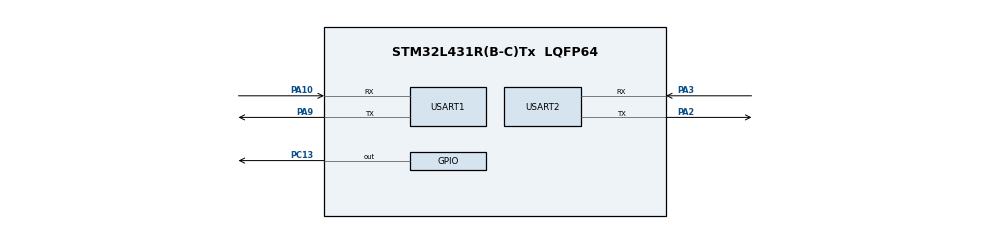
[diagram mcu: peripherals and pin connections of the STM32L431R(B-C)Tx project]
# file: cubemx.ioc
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Mcu.Family=STM32L4
Mcu.Name=STM32L431R(B-C)Tx
Mcu.Package=LQFP64
NVIC.PriorityGroup=NVIC_PRIORITYGROUP_4
NVIC.USART1_IRQn=true\:0\:0\:false\:false\:true\:true\:true
NVIC.USART2_IRQn=true\:0\:0\:false\:false\:true\:true\:true
PA10.Mode=Asynchronous
PA10.Signal=USART1_RX
PA13\ (JTMS-SWDIO).Mode=Serial_Wire
PA13\ (JTMS-SWDIO).Signal=SYS_JTMS-SWDIO
PA14\ (JTCK-SWCLK).Mode=Serial_Wire
PA14\ (JTCK-SWCLK).Signal=SYS_JTCK-SWCLK
PA2.Mode=Asynchronous
PA2.Signal=USART2_TX
PA3.Mode=Asynchronous
PA3.Signal=USART2_RX
PA9.Mode=Asynchronous
PA9.Signal=USART1_TX
PC13.Signal=GPIO_Output
PC14-OSC32_IN\ (PC14).Mode=LSE-External-Oscillator
PC14-OSC32_IN\ (PC14).Signal=RCC_OSC32_IN
PC15-OSC32_OUT\ (PC15).Mode=LSE-External-Oscillator
PC15-OSC32_OUT\ (PC15).Signal=RCC_OSC32_OUT
PH0-OSC_IN\ (PH0).Mode=HSE-External-Oscillator
PH0-OSC_IN\ (PH0).Signal=RCC_OSC_IN
PH1-OSC_OUT\ (PH1).Mode=HSE-External-Oscillator
PH1-OSC_OUT\ (PH1).Signal=RCC_OSC_OUT
ProjectManager.HeapSize=0x200
ProjectManager.StackSize=0x400
ProjectManager.TargetToolchain=MDK-ARM V5.27
RCC.HSE_VALUE=8000000
RCC.HSI48_VALUE=48000000
RCC.HSI_VALUE=16000000
RCC.MSI_VALUE=4000000
RCC.VCOOutputFreq_Value=32000000
USART1.VirtualMode-Asynchronous=VM_ASYNC
USART2.VirtualMode-Asynchronous=VM_ASYNC
board=custom

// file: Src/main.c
/* USER CODE BEGIN Header */
/**
  ******************************************************************************
  * @file           : main.c
  * @brief          : Main program body
  ******************************************************************************
  * @attention
  *
  * <h2><center>&copy; Copyright (c) 2021 STMicroelectronics.
  * All rights reserved.</center></h2>
  *
  * This software component is licensed by ST under BSD 3-Clause license,
  * the "License"; You may not use this file except in compliance with the
  * License. You may obtain a copy of the License at:
  *                        opensource.org/licenses/BSD-3-Clause
  *
  ******************************************************************************
  */
/* USER CODE END Header */
#include "main.h"

UART_HandleTypeDef huart1;
UART_HandleTypeDef huart2;

void SystemClock_Config(void);
static void MX_GPIO_Init(void);
static void MX_USART1_UART_Init(void);
static void MX_USART2_UART_Init(void);

__WEAK int main(void)
{

  /* MCU Configuration--------------------------------------------------------*/

  /* Reset of all peripherals, Initializes the Flash interface and the Systick. */

  /* Infinite loop */
  while (1)
  {

  }
}

void SystemClock_Config(void)
{
  RCC_OscInitTypeDef RCC_OscInitStruct = {0};
  RCC_ClkInitTypeDef RCC_ClkInitStruct = {0};
  RCC_PeriphCLKInitTypeDef PeriphClkInit = {0};

  /** Configure LSE Drive Capability
  */
  HAL_PWR_EnableBkUpAccess();
  __HAL_RCC_LSEDRIVE_CONFIG(RCC_LSEDRIVE_LOW);
  /** Initializes the RCC Oscillators according to the specified parameters
  * in the RCC_OscInitTypeDef structure.
  */
  RCC_OscInitStruct.OscillatorType = RCC_OSCILLATORTYPE_LSE|RCC_OSCILLATORTYPE_MSI;
  RCC_OscInitStruct.LSEState = RCC_LSE_ON;
  RCC_OscInitStruct.MSIState = RCC_MSI_ON;
  RCC_OscInitStruct.MSICalibrationValue = 0;
  RCC_OscInitStruct.MSIClockRange = RCC_MSIRANGE_6;
  RCC_OscInitStruct.PLL.PLLState = RCC_PLL_NONE;
  if (HAL_RCC_OscConfig(&RCC_OscInitStruct) != HAL_OK)
  {
    Error_Handler();
  }
  /** Initializes the CPU, AHB and APB buses clocks
  */
  RCC_ClkInitStruct.ClockType = RCC_CLOCKTYPE_HCLK|RCC_CLOCKTYPE_SYSCLK
                              |RCC_CLOCKTYPE_PCLK1|RCC_CLOCKTYPE_PCLK2;
  RCC_ClkInitStruct.SYSCLKSource = RCC_SYSCLKSOURCE_MSI;
  RCC_ClkInitStruct.AHBCLKDivider = RCC_SYSCLK_DIV1;
  RCC_ClkInitStruct.APB1CLKDivider = RCC_HCLK_DIV1;
  RCC_ClkInitStruct.APB2CLKDivider = RCC_HCLK_DIV1;

  if (HAL_RCC_ClockConfig(&RCC_ClkInitStruct, FLASH_LATENCY_0) != HAL_OK)
  {
    Error_Handler();
  }
  PeriphClkInit.PeriphClockSelection = RCC_PERIPHCLK_USART1|RCC_PERIPHCLK_USART2;
  PeriphClkInit.Usart1ClockSelection = RCC_USART1CLKSOURCE_PCLK2;
  PeriphClkInit.Usart2ClockSelection = RCC_USART2CLKSOURCE_PCLK1;
  if (HAL_RCCEx_PeriphCLKConfig(&PeriphClkInit) != HAL_OK)
  {
    Error_Handler();
  }
  /** Configure the main internal regulator output voltage
  */
  if (HAL_PWREx_ControlVoltageScaling(PWR_REGULATOR_VOLTAGE_SCALE1) != HAL_OK)
  {
    Error_Handler();
  }
  /** Enable MSI Auto calibration
  */
  HAL_RCCEx_EnableMSIPLLMode();
}

static void MX_USART1_UART_Init(void)
{

  huart1.Instance = USART1;
  huart1.Init.BaudRate = 115200;
  huart1.Init.WordLength = UART_WORDLENGTH_8B;
  huart1.Init.StopBits = UART_STOPBITS_1;
  huart1.Init.Parity = UART_PARITY_NONE;
  huart1.Init.Mode = UART_MODE_TX_RX;
  huart1.Init.HwFlowCtl = UART_HWCONTROL_NONE;
  huart1.Init.OverSampling = UART_OVERSAMPLING_16;
  huart1.Init.OneBitSampling = UART_ONE_BIT_SAMPLE_DISABLE;
  huart1.AdvancedInit.AdvFeatureInit = UART_ADVFEATURE_NO_INIT;
  if (HAL_UART_Init(&huart1) != HAL_OK)
  {
    Error_Handler();
  }

}

static void MX_USART2_UART_Init(void)
{

  huart2.Instance = USART2;
  huart2.Init.BaudRate = 115200;
  huart2.Init.WordLength = UART_WORDLENGTH_8B;
  huart2.Init.StopBits = UART_STOPBITS_1;
  huart2.Init.Parity = UART_PARITY_NONE;
  huart2.Init.Mode = UART_MODE_TX_RX;
  huart2.Init.HwFlowCtl = UART_HWCONTROL_NONE;
  huart2.Init.OverSampling = UART_OVERSAMPLING_16;
  huart2.Init.OneBitSampling = UART_ONE_BIT_SAMPLE_DISABLE;
  huart2.AdvancedInit.AdvFeatureInit = UART_ADVFEATURE_NO_INIT;
  if (HAL_UART_Init(&huart2) != HAL_OK)
  {
    Error_Handler();
  }

}

static void MX_GPIO_Init(void)
{
  GPIO_InitTypeDef GPIO_InitStruct = {0};

  /* GPIO Ports Clock Enable */
  __HAL_RCC_GPIOC_CLK_ENABLE();
  __HAL_RCC_GPIOH_CLK_ENABLE();
  __HAL_RCC_GPIOA_CLK_ENABLE();

  /*Configure GPIO pin Output Level */
  HAL_GPIO_WritePin(GPIOC, GPIO_PIN_13, GPIO_PIN_RESET);

  /*Configure GPIO pin : PC13 */
  GPIO_InitStruct.Pin = GPIO_PIN_13;
  GPIO_InitStruct.Mode = GPIO_MODE_OUTPUT_PP;
  GPIO_InitStruct.Pull = GPIO_NOPULL;
  GPIO_InitStruct.Speed = GPIO_SPEED_FREQ_LOW;
  HAL_GPIO_Init(GPIOC, &GPIO_InitStruct);

}

/* USER CODE BEGIN 4 */

void Sys_init(void)
{
    HAL_Init();
    SystemClock_Config();
    MX_GPIO_Init();
    MX_USART1_UART_Init();
    MX_USART2_UART_Init();

}
/* USER CODE END 4 */

void Error_Handler(void)
{
}

/************************ (C) COPYRIGHT STMicroelectronics *****END OF FILE****/
